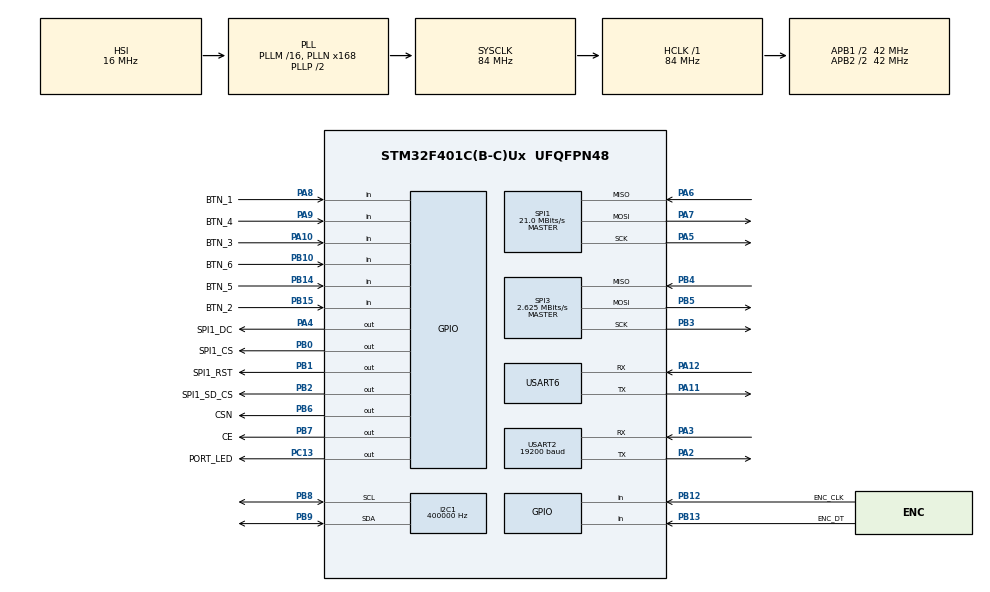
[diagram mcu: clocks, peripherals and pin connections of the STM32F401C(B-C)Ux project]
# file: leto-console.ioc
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Dma.I2C1_TX.0.Direction=DMA_MEMORY_TO_PERIPH
Dma.I2C1_TX.0.FIFOMode=DMA_FIFOMODE_DISABLE
Dma.I2C1_TX.0.Instance=DMA1_Stream6
Dma.I2C1_TX.0.MemDataAlignment=DMA_MDATAALIGN_BYTE
Dma.I2C1_TX.0.MemInc=DMA_MINC_ENABLE
Dma.I2C1_TX.0.Mode=DMA_NORMAL
Dma.I2C1_TX.0.PeriphDataAlignment=DMA_PDATAALIGN_BYTE
Dma.I2C1_TX.0.PeriphInc=DMA_PINC_DISABLE
Dma.I2C1_TX.0.Priority=DMA_PRIORITY_MEDIUM
Dma.Request0=I2C1_TX
Dma.Request1=SPI1_TX
Dma.SPI1_TX.1.Direction=DMA_MEMORY_TO_PERIPH
Dma.SPI1_TX.1.FIFOMode=DMA_FIFOMODE_DISABLE
Dma.SPI1_TX.1.Instance=DMA2_Stream3
Dma.SPI1_TX.1.MemDataAlignment=DMA_MDATAALIGN_BYTE
Dma.SPI1_TX.1.MemInc=DMA_MINC_ENABLE
Dma.SPI1_TX.1.Mode=DMA_NORMAL
Dma.SPI1_TX.1.PeriphDataAlignment=DMA_PDATAALIGN_BYTE
Dma.SPI1_TX.1.PeriphInc=DMA_PINC_DISABLE
Dma.SPI1_TX.1.Priority=DMA_PRIORITY_MEDIUM
I2C1.ClockSpeed=400000
I2C1.I2C_Mode=I2C_Fast
Mcu.Family=STM32F4
Mcu.Name=STM32F401C(B-C)Ux
Mcu.Package=UFQFPN48
NVIC.DMA1_Stream6_IRQn=true\:0\:0\:false\:false\:true\:false\:true\:true
NVIC.DMA2_Stream3_IRQn=true\:0\:0\:false\:false\:true\:false\:true\:true
NVIC.I2C1_EV_IRQn=true\:0\:0\:false\:false\:true\:true\:true\:true
NVIC.PriorityGroup=NVIC_PRIORITYGROUP_4
NVIC.USART2_IRQn=true\:0\:0\:false\:false\:true\:true\:true\:true
NVIC.USART6_IRQn=true\:0\:0\:false\:false\:true\:true\:true\:true
PA10.GPIO_Label=BTN_3
PA10.GPIO_PuPd=GPIO_PULLUP
PA10.Signal=GPIO_Input
PA11.Mode=Asynchronous
PA11.Signal=USART6_TX
PA12.Mode=Asynchronous
PA12.Signal=USART6_RX
PA13.Mode=Serial_Wire
PA13.Signal=SYS_JTMS-SWDIO
PA14.Mode=Serial_Wire
PA14.Signal=SYS_JTCK-SWCLK
PA2.Mode=Asynchronous
PA2.Signal=USART2_TX
PA3.Mode=Asynchronous
PA3.Signal=USART2_RX
PA4.GPIO_Label=SPI1_DC
PA4.Signal=GPIO_Output
PA5.Mode=Full_Duplex_Master
PA5.Signal=SPI1_SCK
PA6.GPIO_PuPd=GPIO_PULLUP
PA6.Mode=Full_Duplex_Master
PA6.Signal=SPI1_MISO
PA7.Mode=Full_Duplex_Master
PA7.Signal=SPI1_MOSI
PA8.GPIO_Label=BTN_1
PA8.GPIO_PuPd=GPIO_PULLUP
PA8.Signal=GPIO_Input
PA9.GPIO_Label=BTN_4
PA9.GPIO_PuPd=GPIO_PULLUP
PA9.Signal=GPIO_Input
PB0.GPIO_Label=SPI1_CS
PB0.GPIO_PuPd=GPIO_PULLUP
PB0.Signal=GPIO_Output
PB1.GPIO_Label=SPI1_RST
PB1.Signal=GPIO_Output
PB10.GPIO_Label=BTN_6
PB10.GPIO_PuPd=GPIO_PULLUP
PB10.Signal=GPIO_Input
PB12.GPIO_Label=ENC_CLK
PB12.GPIO_PuPd=GPIO_PULLUP
PB12.Signal=GPIO_Input
PB13.GPIO_Label=ENC_DT
PB13.GPIO_PuPd=GPIO_PULLUP
PB13.Signal=GPIO_Input
PB14.GPIO_Label=BTN_5
PB14.GPIO_PuPd=GPIO_PULLUP
PB14.Signal=GPIO_Input
PB15.GPIO_Label=BTN_2
PB15.GPIO_PuPd=GPIO_PULLUP
PB15.Signal=GPIO_Input
PB2.GPIO_Label=SPI1_SD_CS
PB2.GPIO_PuPd=GPIO_PULLUP
PB2.Signal=GPIO_Output
PB3.Mode=Full_Duplex_Master
PB3.Signal=SPI3_SCK
PB4.GPIO_PuPd=GPIO_PULLUP
PB4.Mode=Full_Duplex_Master
PB4.Signal=SPI3_MISO
PB5.Mode=Full_Duplex_Master
PB5.Signal=SPI3_MOSI
PB6.GPIO_Label=CSN
PB6.Signal=GPIO_Output
PB7.GPIO_Label=CE
PB7.Signal=GPIO_Output
PB8.Mode=I2C
PB8.Signal=I2C1_SCL
PB9.Mode=I2C
PB9.Signal=I2C1_SDA
PC13-ANTI_TAMP.GPIO_Label=PORT_LED
PC13-ANTI_TAMP.PinState=GPIO_PIN_SET
PC13-ANTI_TAMP.Signal=GPIO_Output
PC14-OSC32_IN.Mode=LSE-External-Oscillator
PC14-OSC32_IN.Signal=RCC_OSC32_IN
PC15-OSC32_OUT.Mode=LSE-External-Oscillator
PC15-OSC32_OUT.Signal=RCC_OSC32_OUT
ProjectManager.HeapSize=0x200
ProjectManager.StackSize=0x400
ProjectManager.TargetToolchain=STM32CubeIDE
RCC.48MHZClocksFreq_Value=42000000
RCC.AHBFreq_Value=84000000
RCC.APB1CLKDivider=RCC_HCLK_DIV2
RCC.APB1Freq_Value=42000000
RCC.APB1TimFreq_Value=84000000
RCC.APB2CLKDivider=RCC_HCLK_DIV2
RCC.APB2Freq_Value=42000000
RCC.APB2TimFreq_Value=84000000
RCC.CortexFreq_Value=84000000
RCC.HCLKFreq_Value=84000000
RCC.HSE_VALUE=25000000
RCC.HSI_VALUE=16000000
RCC.PLLN=168
RCC.RCC_RTC_Clock_Source=RCC_RTCCLKSOURCE_LSE
RCC.RCC_RTC_Clock_SourceVirtual=RCC_RTCCLKSOURCE_LSE
RCC.SYSCLKFreq_VALUE=84000000
RCC.SYSCLKSource=RCC_SYSCLKSOURCE_PLLCLK
RCC.VCOOutputFreq_Value=168000000
RTC.Hours=0
SPI1.BaudRatePrescaler=SPI_BAUDRATEPRESCALER_2
SPI1.CalculateBaudRate=21.0 MBits/s
SPI1.Direction=SPI_DIRECTION_2LINES
SPI1.Mode=SPI_MODE_MASTER
SPI1.VirtualType=VM_MASTER
SPI3.BaudRatePrescaler=SPI_BAUDRATEPRESCALER_16
SPI3.CalculateBaudRate=2.625 MBits/s
SPI3.Direction=SPI_DIRECTION_2LINES
SPI3.Mode=SPI_MODE_MASTER
SPI3.VirtualType=VM_MASTER
USART2.BaudRate=19200
USART2.VirtualMode=VM_ASYNC
USART2.WordLength=WORDLENGTH_8B
USART6.VirtualMode=VM_ASYNC
VP_CRC_VS_CRC.Mode=CRC_Activate
VP_RTC_VS_RTC_Activate.Mode=RTC_Enabled
VP_RTC_VS_RTC_Calendar.Mode=RTC_Calendar
VP_TIM1_VS_ClockSourceINT.Mode=Internal
board=custom

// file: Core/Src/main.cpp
/* USER CODE BEGIN Header */
/**
  ******************************************************************************
  * @file           : main.c
  * @brief          : Main program body
  ******************************************************************************
  * @attention
  *
  * Copyright (c) 2025 STMicroelectronics.
  * All rights reserved.
  *
  * This software is licensed under terms that can be found in the LICENSE file
  * in the root directory of this software component.
  * If no LICENSE file comes with this software, it is provided AS-IS.
  *
  ******************************************************************************
  */
/* USER CODE END Header */
#include "main.h"

/* USER CODE BEGIN Includes */
#include "project_includes.hpp"
/* USER CODE END Includes */

CRC_HandleTypeDef hcrc;

I2C_HandleTypeDef hi2c1;
DMA_HandleTypeDef hdma_i2c1_tx;

RTC_HandleTypeDef hrtc;

SPI_HandleTypeDef hspi1;
SPI_HandleTypeDef hspi3;
DMA_HandleTypeDef hdma_spi1_tx;

TIM_HandleTypeDef htim1;

UART_HandleTypeDef huart2;
UART_HandleTypeDef huart6;

/* USER CODE BEGIN PV */
Application::Periphery periphery =
{
	.hi2c = &hi2c1,
	.htim = nullptr,
	.huart_console = &huart2,
	.huart_web = &huart6,
	.hrtc = &hrtc,
};
Application app{ periphery };
/* USER CODE END PV */

void SystemClock_Config(void);
static void MX_GPIO_Init(void);
static void MX_DMA_Init(void);
static void MX_USART2_UART_Init(void);
static void MX_I2C1_Init(void);
static void MX_TIM1_Init(void);
static void MX_USART6_UART_Init(void);
static void MX_CRC_Init(void);
static void MX_RTC_Init(void);
static void MX_SPI3_Init(void);
static void MX_SPI1_Init(void);
/* USER CODE BEGIN PFP */
#include <UART/UART_printf_prototype.hpp>
#include <UART/UART_console_init.hpp>
#include <CommandHandler/CommandHandler.hpp>
#include <LetoAPI_V1_System/Web/WebPacketParser.hpp>
#include <LetoAPI_V1/Web/WebConnection.h>
//#include <NRF24L01/nrf24l01.h>
/* USER CODE END PFP */

/* USER CODE BEGIN 0 */
static uint8_t buffer2, buffer6;

void HAL_UART_RxCpltCallback(UART_HandleTypeDef *huart)
{
	if (huart->Instance == USART2)
	{
		if (!uart_log_enabled)
			return;

		HAL_UART_Receive_IT(huart, &buffer2, 1);

        if((buffer2 == '\x08')||(buffer2 == '\x7F'))  // backspace
        {
        	const char del[] = "\x08 \x08";
			HAL_UART_Transmit(huart, (uint8_t*)del, sizeof(del)-1, 1000);
        }
        else if((buffer2 == '\r') || (buffer2 == '\n'))
        {
        	const char nl[] = "\r\n";
            HAL_UART_Transmit(huart, (uint8_t*)nl, sizeof(nl)-1, 1000);
        }
        else
        {
    		HAL_UART_Transmit(huart, &buffer2, 1, 1000);
        }

		CommandHandler::Callback((char) buffer2);
	}
	else if (huart->Instance == USART6)
	{
		HAL_UART_Receive_IT(huart, &buffer6, 1);
		WebPacketParser::CallbackByte(WC_CHANNEL_UART, buffer6);
	}
}
/* USER CODE END 0 */

#include "ProjectSettings/ProjectSettings.hpp"
#include <NRF24L01/NRF24L01_data.hpp>

int main(void)
{

  /* MCU Configuration--------------------------------------------------------*/

  /* Reset of all peripherals, Initializes the Flash interface and the Systick. */
   HAL_Init();

  /* Configure the system clock */
  SystemClock_Config();

  /* Initialize all configured peripherals */
  MX_GPIO_Init();
  MX_DMA_Init();
  MX_USART2_UART_Init();
  MX_I2C1_Init();
  MX_TIM1_Init();
  MX_USART6_UART_Init();
  MX_CRC_Init();
  MX_RTC_Init();
  MX_SPI3_Init();
  MX_SPI1_Init();
  /* USER CODE BEGIN 2 */
#if 0
  DWT_Init(); // счётчик для микросекундных пауз

  uint8_t res = isChipConnected(); // проверяет подключён ли модуль к SPI

  char str[64] = {0,};
  snprintf(str, 64, "Connected: %s\n\r", 1 ? "OK" : "NOT OK");
  HAL_UART_Transmit(&huart2, (uint8_t*)str, strlen(str), 1000);

  res = NRF_Init(); // инициализация

  snprintf(str, 64, "Init: %s\n\r", res > 0 && res < 255 ? "OK" : "NOT OK");
  HAL_UART_Transmit(&huart2, (uint8_t*)str, strlen(str), 1000);

  snprintf(str, 64, "P-variant: %d\n\r", isPVariant());
  HAL_UART_Transmit(&huart2, (uint8_t*)str, strlen(str), 1000);

  ////////////// SET ////////////////
  //enableAckPayload();
  setAddressWidth(4); // Я ДОБАВИЛ
  setAutoAck(true);
  //setPayloadSize(3);
  setChannel(32);
  // Delay: 1 (500mks), count: 5
  setRetries(1, 5);

  ///////////////////////////////////

  ////////////////////////// Вывод всяких статусов, для работы не нужно /////////////////////////////
  uint8_t status = get_status();
  snprintf(str, 64, "get_status: 0x%02x\n\r", status);
  HAL_UART_Transmit(&huart2, (uint8_t*)str, strlen(str), 1000);

  status = getPALevel();
  snprintf(str, 64, "getPALevel: 0x%02x  ", status);
  HAL_UART_Transmit(&huart2, (uint8_t*)str, strlen(str), 1000);

  if(status == 0x00)
  {
	  HAL_UART_Transmit(&huart2, (uint8_t*)"RF24_PA_MIN\n\r", strlen("RF24_PA_MIN\n\r"), 1000);
  }
  else if(status == 0x01)
  {
	  HAL_UART_Transmit(&huart2, (uint8_t*)"RF24_PA_LOW\n\r", strlen("RF24_PA_LOW\n\r"), 1000);
  }
  else if(status == 0x02)
  {
	  HAL_UART_Transmit(&huart2, (uint8_t*)"RF24_PA_HIGH\n\r", strlen("RF24_PA_HIGH\n\r"), 1000);
  }
  else if(status == 0x03)
  {
	  HAL_UART_Transmit(&huart2, (uint8_t*)"RF24_PA_MAX\n\r", strlen("RF24_PA_MAX\n\r"), 1000);
  }

  status = getChannel();
  snprintf(str, 64, "getChannel: 0x%02x № %d\n\r", status, status);
  HAL_UART_Transmit(&huart2, (uint8_t*)str, strlen(str), 1000);

  status = getDataRate();
  snprintf(str, 64, "getDataRate: 0x%02x  ", status);
  HAL_UART_Transmit(&huart2, (uint8_t*)str, strlen(str), 1000);

  if(status == 0x02)
  {
	  HAL_UART_Transmit(&huart2, (uint8_t*)"RF24_250KBPS\n\r", strlen("RF24_250KBPS\n\r"), 1000);
  }
  else if(status == 0x01)
  {
	  HAL_UART_Transmit(&huart2, (uint8_t*)"RF24_2MBPS\n\r", strlen("RF24_2MBPS\n\r"), 1000);
  }
  else
  {
	  HAL_UART_Transmit(&huart2, (uint8_t*)"RF24_1MBPS\n\r", strlen("RF24_1MBPS\n\r"), 1000);
  }

  status = getPayloadSize();
  snprintf(str, 64, "getPayloadSize: %d\n\r", status);
  HAL_UART_Transmit(&huart2, (uint8_t*)str, strlen(str), 1000);

  status = getCRCLength();
  snprintf(str, 64, "getCRCLength: 0x%02x  ", status);
  HAL_UART_Transmit(&huart2, (uint8_t*)str, strlen(str), 1000);

  if(status == 0x00)
  {
	  HAL_UART_Transmit(&huart2, (uint8_t*)"RF24_CRC_DISABLED\n\r", strlen("RF24_CRC_DISABLED\n\r"), 1000);
  }
  else if(status == 0x01)
  {
	  HAL_UART_Transmit(&huart2, (uint8_t*)"RF24_CRC_8\n\r", strlen("RF24_CRC_8\n\r"), 1000);
  }
  else if(status == 0x02)
  {
	  HAL_UART_Transmit(&huart2, (uint8_t*)"RF24_CRC_16\n\r", strlen("RF24_CRC_16\n\r"), 1000);
  }
  /////////////////////////////////////////////////////////////////////////////////////////////////////

  maskIRQ(true, true, true); // маскируем прерывания
#endif
  app.Init();
  /* USER CODE END 2 */

  /* Infinite loop */
  /* USER CODE BEGIN WHILE */
  HAL_UART_Receive_IT(&huart2, &buffer2, 1);
  HAL_UART_Receive_IT(&huart6, &buffer6, 1);
  HAL_TIM_Base_Start_IT(&htim1);
  while (1)
  {
	  app.Loop();

	    /* USER CODE END WHILE */

  }
}

void SystemClock_Config(void)
{
  RCC_OscInitTypeDef RCC_OscInitStruct = {0};
  RCC_ClkInitTypeDef RCC_ClkInitStruct = {0};

  /** Configure the main internal regulator output voltage
  */
  __HAL_RCC_PWR_CLK_ENABLE();
  __HAL_PWR_VOLTAGESCALING_CONFIG(PWR_REGULATOR_VOLTAGE_SCALE2);

  /** Initializes the RCC Oscillators according to the specified parameters
  * in the RCC_OscInitTypeDef structure.
  */
  RCC_OscInitStruct.OscillatorType = RCC_OSCILLATORTYPE_HSI|RCC_OSCILLATORTYPE_LSE;
  RCC_OscInitStruct.LSEState = RCC_LSE_ON;
  RCC_OscInitStruct.HSIState = RCC_HSI_ON;
  RCC_OscInitStruct.HSICalibrationValue = RCC_HSICALIBRATION_DEFAULT;
  RCC_OscInitStruct.PLL.PLLState = RCC_PLL_ON;
  RCC_OscInitStruct.PLL.PLLSource = RCC_PLLSOURCE_HSI;
  RCC_OscInitStruct.PLL.PLLM = 16;
  RCC_OscInitStruct.PLL.PLLN = 168;
  RCC_OscInitStruct.PLL.PLLP = RCC_PLLP_DIV2;
  RCC_OscInitStruct.PLL.PLLQ = 4;
  if (HAL_RCC_OscConfig(&RCC_OscInitStruct) != HAL_OK)
  {
    Error_Handler();
  }

  /** Initializes the CPU, AHB and APB buses clocks
  */
  RCC_ClkInitStruct.ClockType = RCC_CLOCKTYPE_HCLK|RCC_CLOCKTYPE_SYSCLK
                              |RCC_CLOCKTYPE_PCLK1|RCC_CLOCKTYPE_PCLK2;
  RCC_ClkInitStruct.SYSCLKSource = RCC_SYSCLKSOURCE_PLLCLK;
  RCC_ClkInitStruct.AHBCLKDivider = RCC_SYSCLK_DIV1;
  RCC_ClkInitStruct.APB1CLKDivider = RCC_HCLK_DIV2;
  RCC_ClkInitStruct.APB2CLKDivider = RCC_HCLK_DIV2;

  if (HAL_RCC_ClockConfig(&RCC_ClkInitStruct, FLASH_LATENCY_2) != HAL_OK)
  {
    Error_Handler();
  }
}

static void MX_CRC_Init(void)
{

  hcrc.Instance = CRC;
  if (HAL_CRC_Init(&hcrc) != HAL_OK)
  {
    Error_Handler();
  }

}

static void MX_I2C1_Init(void)
{

  hi2c1.Instance = I2C1;
  hi2c1.Init.ClockSpeed = 400000;
  hi2c1.Init.DutyCycle = I2C_DUTYCYCLE_2;
  hi2c1.Init.OwnAddress1 = 0;
  hi2c1.Init.AddressingMode = I2C_ADDRESSINGMODE_7BIT;
  hi2c1.Init.DualAddressMode = I2C_DUALADDRESS_DISABLE;
  hi2c1.Init.OwnAddress2 = 0;
  hi2c1.Init.GeneralCallMode = I2C_GENERALCALL_DISABLE;
  hi2c1.Init.NoStretchMode = I2C_NOSTRETCH_DISABLE;
  if (HAL_I2C_Init(&hi2c1) != HAL_OK)
  {
    Error_Handler();
  }

}

static void MX_RTC_Init(void)
{

  RTC_TimeTypeDef sTime = {0};
  RTC_DateTypeDef sDate = {0};

  /** Initialize RTC Only
  */
  hrtc.Instance = RTC;
  hrtc.Init.HourFormat = RTC_HOURFORMAT_24;
  hrtc.Init.AsynchPrediv = 127;
  hrtc.Init.SynchPrediv = 255;
  hrtc.Init.OutPut = RTC_OUTPUT_DISABLE;
  hrtc.Init.OutPutPolarity = RTC_OUTPUT_POLARITY_HIGH;
  hrtc.Init.OutPutType = RTC_OUTPUT_TYPE_OPENDRAIN;
  if (HAL_RTC_Init(&hrtc) != HAL_OK)
  {
    Error_Handler();
  }

  /* USER CODE BEGIN Check_RTC_BKUP */
  return; // Остальное инициализируем сами
  /* USER CODE END Check_RTC_BKUP */

  /** Initialize RTC and set the Time and Date
  */
  sTime.Hours = 0x0;
  sTime.Minutes = 0x0;
  sTime.Seconds = 0x0;
  sTime.DayLightSaving = RTC_DAYLIGHTSAVING_NONE;
  sTime.StoreOperation = RTC_STOREOPERATION_RESET;
  if (HAL_RTC_SetTime(&hrtc, &sTime, RTC_FORMAT_BCD) != HAL_OK)
  {
    Error_Handler();
  }
  sDate.WeekDay = RTC_WEEKDAY_MONDAY;
  sDate.Month = RTC_MONTH_JANUARY;
  sDate.Date = 0x1;
  sDate.Year = 0x0;

  if (HAL_RTC_SetDate(&hrtc, &sDate, RTC_FORMAT_BCD) != HAL_OK)
  {
    Error_Handler();
  }

}
static void MX_SPI1_Init(void)
{

  /* SPI1 parameter configuration*/
  hspi1.Instance = SPI1;
  hspi1.Init.Mode = SPI_MODE_MASTER;
  hspi1.Init.Direction = SPI_DIRECTION_2LINES;
  hspi1.Init.DataSize = SPI_DATASIZE_8BIT;
  hspi1.Init.CLKPolarity = SPI_POLARITY_LOW;
  hspi1.Init.CLKPhase = SPI_PHASE_1EDGE;
  hspi1.Init.NSS = SPI_NSS_SOFT;
  hspi1.Init.BaudRatePrescaler = SPI_BAUDRATEPRESCALER_2;
  hspi1.Init.FirstBit = SPI_FIRSTBIT_MSB;
  hspi1.Init.TIMode = SPI_TIMODE_DISABLE;
  hspi1.Init.CRCCalculation = SPI_CRCCALCULATION_DISABLE;
  hspi1.Init.CRCPolynomial = 10;
  if (HAL_SPI_Init(&hspi1) != HAL_OK)
  {
    Error_Handler();
  }

}

static void MX_SPI3_Init(void)
{

  /* SPI3 parameter configuration*/
  hspi3.Instance = SPI3;
  hspi3.Init.Mode = SPI_MODE_MASTER;
  hspi3.Init.Direction = SPI_DIRECTION_2LINES;
  hspi3.Init.DataSize = SPI_DATASIZE_8BIT;
  hspi3.Init.CLKPolarity = SPI_POLARITY_LOW;
  hspi3.Init.CLKPhase = SPI_PHASE_1EDGE;
  hspi3.Init.NSS = SPI_NSS_SOFT;
  hspi3.Init.BaudRatePrescaler = SPI_BAUDRATEPRESCALER_16;
  hspi3.Init.FirstBit = SPI_FIRSTBIT_MSB;
  hspi3.Init.TIMode = SPI_TIMODE_DISABLE;
  hspi3.Init.CRCCalculation = SPI_CRCCALCULATION_DISABLE;
  hspi3.Init.CRCPolynomial = 10;
  if (HAL_SPI_Init(&hspi3) != HAL_OK)
  {
    Error_Handler();
  }

}

static void MX_TIM1_Init(void)
{

  TIM_ClockConfigTypeDef sClockSourceConfig = {0};
  TIM_MasterConfigTypeDef sMasterConfig = {0};

  htim1.Instance = TIM1;
  htim1.Init.Prescaler = 4199;
  htim1.Init.CounterMode = TIM_COUNTERMODE_UP;
  //htim1.Init.Period = 1999;
  htim1.Init.Period = 49;
  htim1.Init.ClockDivision = TIM_CLOCKDIVISION_DIV1;
  htim1.Init.RepetitionCounter = 0;
  htim1.Init.AutoReloadPreload = TIM_AUTORELOAD_PRELOAD_DISABLE;
  if (HAL_TIM_Base_Init(&htim1) != HAL_OK)
  {
    Error_Handler();
  }
  sClockSourceConfig.ClockSource = TIM_CLOCKSOURCE_INTERNAL;
  if (HAL_TIM_ConfigClockSource(&htim1, &sClockSourceConfig) != HAL_OK)
  {
    Error_Handler();
  }
  sMasterConfig.MasterOutputTrigger = TIM_TRGO_RESET;
  sMasterConfig.MasterSlaveMode = TIM_MASTERSLAVEMODE_DISABLE;
  if (HAL_TIMEx_MasterConfigSynchronization(&htim1, &sMasterConfig) != HAL_OK)
  {
    Error_Handler();
  }
  /* USER CODE BEGIN TIM1_Init 2 */
  HAL_NVIC_SetPriority(TIM1_UP_TIM10_IRQn, 0, 0);
  HAL_NVIC_EnableIRQ(TIM1_UP_TIM10_IRQn);
  /* USER CODE END TIM1_Init 2 */

}

static void MX_USART2_UART_Init(void)
{

  huart2.Instance = USART2;
  huart2.Init.BaudRate = 19200;
  huart2.Init.WordLength = UART_WORDLENGTH_8B;
  huart2.Init.StopBits = UART_STOPBITS_1;
  huart2.Init.Parity = UART_PARITY_NONE;
  huart2.Init.Mode = UART_MODE_TX_RX;
  huart2.Init.HwFlowCtl = UART_HWCONTROL_NONE;
  huart2.Init.OverSampling = UART_OVERSAMPLING_16;
  if (HAL_UART_Init(&huart2) != HAL_OK)
  {
    Error_Handler();
  }

}

static void MX_USART6_UART_Init(void)
{

  huart6.Instance = USART6;
  huart6.Init.BaudRate = 115200;
  huart6.Init.WordLength = UART_WORDLENGTH_8B;
  huart6.Init.StopBits = UART_STOPBITS_1;
  huart6.Init.Parity = UART_PARITY_NONE;
  huart6.Init.Mode = UART_MODE_TX_RX;
  huart6.Init.HwFlowCtl = UART_HWCONTROL_NONE;
  huart6.Init.OverSampling = UART_OVERSAMPLING_16;
  if (HAL_UART_Init(&huart6) != HAL_OK)
  {
    Error_Handler();
  }

}

static void MX_DMA_Init(void)
{

  /* DMA controller clock enable */
  __HAL_RCC_DMA1_CLK_ENABLE();
  __HAL_RCC_DMA2_CLK_ENABLE();

  /* DMA interrupt init */
  /* DMA1_Stream6_IRQn interrupt configuration */
  HAL_NVIC_SetPriority(DMA1_Stream6_IRQn, 0, 0);
  HAL_NVIC_EnableIRQ(DMA1_Stream6_IRQn);
  /* DMA2_Stream3_IRQn interrupt configuration */
  HAL_NVIC_SetPriority(DMA2_Stream3_IRQn, 0, 0);
  HAL_NVIC_EnableIRQ(DMA2_Stream3_IRQn);

}

static void MX_GPIO_Init(void)
{
  GPIO_InitTypeDef GPIO_InitStruct = {0};

  /* GPIO Ports Clock Enable */
  __HAL_RCC_GPIOC_CLK_ENABLE();
  __HAL_RCC_GPIOA_CLK_ENABLE();
  __HAL_RCC_GPIOB_CLK_ENABLE();

  /*Configure GPIO pin Output Level */
  HAL_GPIO_WritePin(PORT_LED_GPIO_Port, PORT_LED_Pin, GPIO_PIN_SET);

  /*Configure GPIO pin Output Level */
  HAL_GPIO_WritePin(SPI1_DC_GPIO_Port, SPI1_DC_Pin, GPIO_PIN_RESET);

  /*Configure GPIO pin Output Level */
  HAL_GPIO_WritePin(GPIOB, SPI1_CS_Pin|SPI1_RST_Pin|SPI1_SD_CS_Pin|CSN_Pin
                          |CE_Pin, GPIO_PIN_RESET);

  /*Configure GPIO pin : PORT_LED_Pin */
  GPIO_InitStruct.Pin = PORT_LED_Pin;
  GPIO_InitStruct.Mode = GPIO_MODE_OUTPUT_PP;
  GPIO_InitStruct.Pull = GPIO_NOPULL;
  GPIO_InitStruct.Speed = GPIO_SPEED_FREQ_LOW;
  HAL_GPIO_Init(PORT_LED_GPIO_Port, &GPIO_InitStruct);

  /*Configure GPIO pin : SPI1_DC_Pin */
  GPIO_InitStruct.Pin = SPI1_DC_Pin;
  GPIO_InitStruct.Mode = GPIO_MODE_OUTPUT_PP;
  GPIO_InitStruct.Pull = GPIO_NOPULL;
  GPIO_InitStruct.Speed = GPIO_SPEED_FREQ_LOW;
  HAL_GPIO_Init(SPI1_DC_GPIO_Port, &GPIO_InitStruct);

  /*Configure GPIO pins : SPI1_CS_Pin SPI1_SD_CS_Pin */
  GPIO_InitStruct.Pin = SPI1_CS_Pin|SPI1_SD_CS_Pin;
  GPIO_InitStruct.Mode = GPIO_MODE_OUTPUT_PP;
  GPIO_InitStruct.Pull = GPIO_PULLUP;
  GPIO_InitStruct.Speed = GPIO_SPEED_FREQ_LOW;
  HAL_GPIO_Init(GPIOB, &GPIO_InitStruct);

  /*Configure GPIO pins : SPI1_RST_Pin CSN_Pin CE_Pin */
  GPIO_InitStruct.Pin = SPI1_RST_Pin|CSN_Pin|CE_Pin;
  GPIO_InitStruct.Mode = GPIO_MODE_OUTPUT_PP;
  GPIO_InitStruct.Pull = GPIO_NOPULL;
  GPIO_InitStruct.Speed = GPIO_SPEED_FREQ_LOW;
  HAL_GPIO_Init(GPIOB, &GPIO_InitStruct);

  /*Configure GPIO pins : BTN_6_Pin ENC_CLK_Pin ENC_DT_Pin BTN_5_Pin
                           BTN_2_Pin */
  GPIO_InitStruct.Pin = BTN_6_Pin|ENC_CLK_Pin|ENC_DT_Pin|BTN_5_Pin
                          |BTN_2_Pin;
  GPIO_InitStruct.Mode = GPIO_MODE_INPUT;
  GPIO_InitStruct.Pull = GPIO_PULLUP;
  HAL_GPIO_Init(GPIOB, &GPIO_InitStruct);

  /*Configure GPIO pins : BTN_1_Pin BTN_4_Pin BTN_3_Pin BTN_7_Pin */
  GPIO_InitStruct.Pin = BTN_1_Pin|BTN_4_Pin|BTN_3_Pin|BTN_7_Pin;
  GPIO_InitStruct.Mode = GPIO_MODE_INPUT;
  GPIO_InitStruct.Pull = GPIO_PULLUP;
  HAL_GPIO_Init(GPIOA, &GPIO_InitStruct);

}

void Error_Handler(void)
{
  __disable_irq();
  while (1)
  {
  }
}
